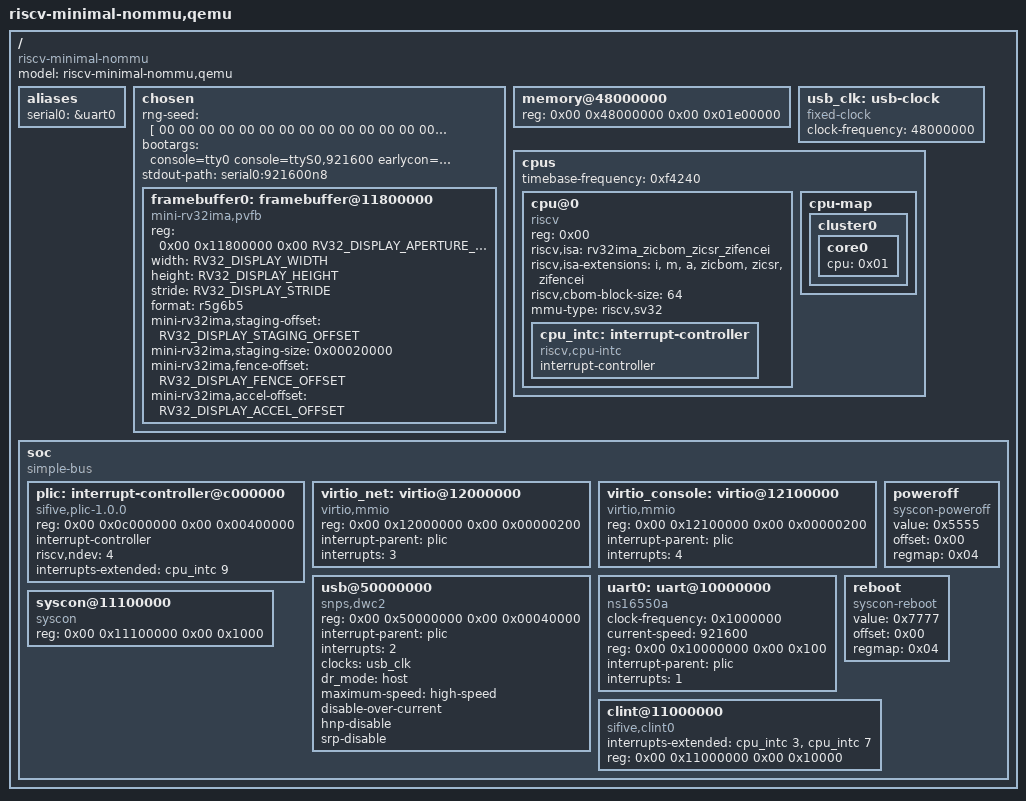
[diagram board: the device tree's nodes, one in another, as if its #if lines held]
/dts-v1/;

/ {
	#address-cells = <0x02>;
	#size-cells = <0x02>;
	compatible = "riscv-minimal-nommu";
	model = "riscv-minimal-nommu,qemu";

	aliases {
		serial0 = &uart0;
	};

	chosen {
		#address-cells = <2>;
		#size-cells = <2>;
		ranges;
		rng-seed = [
			00 00 00 00 00 00 00 00 00 00 00 00 00 00 00 00
			00 00 00 00 00 00 00 00 00 00 00 00 00 00 00 00
			00 00 00 00 00 00 00 00 00 00 00 00 00 00 00 00
			00 00 00 00 00 00 00 00 00 00 00 00 00 00 00 00
		];
#if RV32_DISPLAY_ENABLED
		bootargs = "console=tty0 console=ttyS0,921600 earlycon=uart8250,mmio,0x10000000,16550a quiet loglevel=3";
#else
		bootargs = "console=ttyS0,921600 earlycon=uart8250,mmio,0x10000000,16550a quiet loglevel=3";
#endif
		stdout-path = "serial0:921600n8";

	#if RV32_DISPLAY_ENABLED
		framebuffer0: framebuffer@11800000 {
			/* The second compatible keeps unmodified kernel Images usable. */
			compatible = "mini-rv32ima,pvfb", "simple-framebuffer";
			/* Scanout followed by generic staging and command apertures. */
			reg = <0x00 0x11800000 0x00 RV32_DISPLAY_APERTURE_SIZE>;
			width = <RV32_DISPLAY_WIDTH>;
			height = <RV32_DISPLAY_HEIGHT>;
			stride = <RV32_DISPLAY_STRIDE>;
			format = "r5g6b5";
			mini-rv32ima,staging-offset = <RV32_DISPLAY_STAGING_OFFSET>;
			mini-rv32ima,staging-size = <0x00020000>;
			mini-rv32ima,fence-offset = <RV32_DISPLAY_FENCE_OFFSET>;
			mini-rv32ima,accel-offset = <RV32_DISPLAY_ACCEL_OFFSET>;
			status = "okay";
		};
#endif
	};

	memory@48000000 {
		device_type = "memory";
		reg = <0x00 0x48000000 0x00 0x01e00000>;
	};

	usb_clk: usb-clock {
		compatible = "fixed-clock";
		#clock-cells = <0>;
		clock-frequency = <48000000>;
	};

	cpus {
		#address-cells = <0x01>;
		#size-cells = <0x00>;
		timebase-frequency = <0xf4240>;

		cpu@0 {
			phandle = <0x01>;
			device_type = "cpu";
			reg = <0x00>;
			status = "okay";
			compatible = "riscv";
			riscv,isa = "rv32ima_zicbom_zicsr_zifencei";
			riscv,isa-extensions = "i", "m", "a", "zicbom", "zicsr", "zifencei";
			riscv,cbom-block-size = <64>;
			mmu-type = "riscv,sv32";

			cpu_intc: interrupt-controller {
				#interrupt-cells = <0x01>;
				interrupt-controller;
				compatible = "riscv,cpu-intc";
				phandle = <0x02>;
			};
		};

		cpu-map {

			cluster0 {

				core0 {
					cpu = <0x01>;
				};
			};
		};
	};

	soc {
		#address-cells = <0x02>;
		#size-cells = <0x02>;
		compatible = "simple-bus";
		ranges;

		plic: interrupt-controller@c000000 {
			compatible = "sifive,plic-1.0.0", "riscv,plic0";
			reg = <0x00 0x0c000000 0x00 0x00400000>;
			#interrupt-cells = <1>;
			interrupt-controller;
			/* UART, USB, optional virtio-net, and virtio-console. */
			riscv,ndev = <4>;
			interrupts-extended = <&cpu_intc 9>;
		};

#if RV32_WIFI_BRIDGE
		virtio_net: virtio@12000000 {
			compatible = "virtio,mmio";
			reg = <0x00 0x12000000 0x00 0x00000200>;
			interrupt-parent = <&plic>;
			interrupts = <3>;
		};
#endif

		virtio_console: virtio@12100000 {
			compatible = "virtio,mmio";
			reg = <0x00 0x12100000 0x00 0x00000200>;
			interrupt-parent = <&plic>;
			interrupts = <4>;
		};

		usb@50000000 {
			compatible = "snps,dwc2";
			reg = <0x00 0x50000000 0x00 0x00040000>;
			interrupt-parent = <&plic>;
			interrupts = <2>;
			clocks = <&usb_clk>;
			clock-names = "otg";
			dr_mode = "host";
			maximum-speed = "high-speed";
			disable-over-current;
			hnp-disable;
			srp-disable;
		};

		uart0: uart@10000000 {
  		 	clock-frequency = <0x1000000>;
			current-speed = <921600>;
		    reg = <0x00 0x10000000 0x00 0x100>;
		    compatible = "ns16550a";
			interrupt-parent = <&plic>;
			interrupts = <1>;
		};

		poweroff {
			value = <0x5555>;
			offset = <0x00>;
			regmap = <0x04>;
			compatible = "syscon-poweroff";
		};

		reboot {
			value = <0x7777>;
			offset = <0x00>;
			regmap = <0x04>;
			compatible = "syscon-reboot";
		};

		syscon@11100000 {
			phandle = <0x04>;
			reg = <0x00 0x11100000 0x00 0x1000>;
			compatible = "syscon";
		};

		clint@11000000 {
			interrupts-extended = <&cpu_intc 3 &cpu_intc 7>;
			reg = <0x00 0x11000000 0x00 0x10000>;
			compatible = "sifive,clint0", "riscv,clint0";
		};
	};
};
